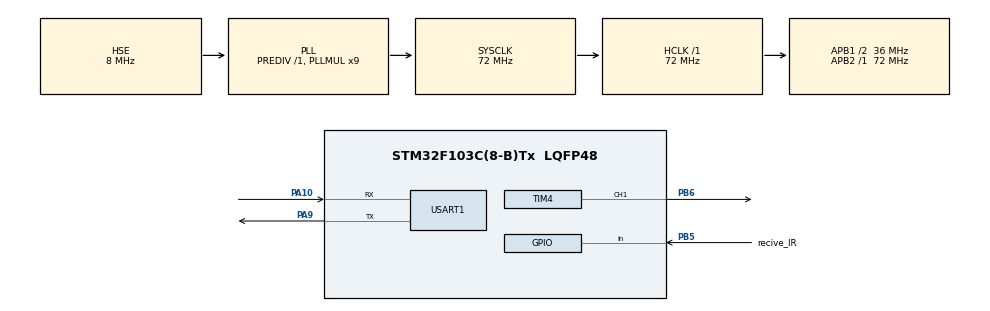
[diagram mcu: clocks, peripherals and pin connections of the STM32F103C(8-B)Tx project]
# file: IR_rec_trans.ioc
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Mcu.Family=STM32F1
Mcu.Name=STM32F103C(8-B)Tx
Mcu.Package=LQFP48
NVIC.PriorityGroup=NVIC_PRIORITYGROUP_4
NVIC.TIM4_IRQn=true\:0\:0\:false\:false\:true\:true\:true
PA10.Mode=Asynchronous
PA10.Signal=USART1_RX
PA13.Mode=Serial_Wire
PA13.Signal=SYS_JTMS-SWDIO
PA14.Mode=Serial_Wire
PA14.Signal=SYS_JTCK-SWCLK
PA9.Mode=Asynchronous
PA9.Signal=USART1_TX
PB5.GPIO_Label=recive_IR
PB5.Signal=GPIO_Input
PB6.Signal=S_TIM4_CH1
PD0-OSC_IN.Mode=HSE-External-Oscillator
PD0-OSC_IN.Signal=RCC_OSC_IN
PD1-OSC_OUT.Mode=HSE-External-Oscillator
PD1-OSC_OUT.Signal=RCC_OSC_OUT
ProjectManager.HeapSize=0x200
ProjectManager.StackSize=0x400
ProjectManager.TargetToolchain=TrueSTUDIO
RCC.AHBFreq_Value=72000000
RCC.APB1CLKDivider=RCC_HCLK_DIV2
RCC.APB1Freq_Value=36000000
RCC.APB1TimFreq_Value=72000000
RCC.APB2Freq_Value=72000000
RCC.APB2TimFreq_Value=72000000
RCC.HCLKFreq_Value=72000000
RCC.PLLMUL=RCC_PLL_MUL9
RCC.PLLSourceVirtual=RCC_PLLSOURCE_HSE
RCC.SYSCLKFreq_VALUE=72000000
RCC.SYSCLKSource=RCC_SYSCLKSOURCE_PLLCLK
RCC.USBFreq_Value=72000000
SH.S_TIM4_CH1.0=TIM4_CH1,PWM Generation1 CH1
TIM4.Channel-PWM\ Generation1\ CH1=TIM_CHANNEL_1
TIM4.OCPolarity_1=TIM_OCPOLARITY_HIGH
TIM4.Period=0
TIM4.Prescaler=0
USART1.VirtualMode=VM_ASYNC
VP_TIM4_VS_ClockSourceINT.Mode=Internal
board=custom

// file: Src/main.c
/* USER CODE BEGIN Header */
/**
  ******************************************************************************
  * @file           : main.c
  * @brief          : Main program body
  ******************************************************************************
  * @attention
  *
  * <h2><center>&copy; Copyright (c) 2019 STMicroelectronics.
  * All rights reserved.</center></h2>
  *
  * This software component is licensed by ST under BSD 3-Clause license,
  * the "License"; You may not use this file except in compliance with the
  * License. You may obtain a copy of the License at:
  *                        opensource.org/licenses/BSD-3-Clause
  *
  ******************************************************************************
  */
/* USER CODE END Header */

#include "main.h"

/* USER CODE BEGIN Includes */
#include "string.h"
#include "IRremote.h"
/* USER CODE END Includes */

TIM_HandleTypeDef htim4;

UART_HandleTypeDef huart1;

void SystemClock_Config(void);
static void MX_GPIO_Init(void);
static void MX_USART1_UART_Init(void);
static void MX_TIM4_Init(void);

int main(void)
{

  /* MCU Configuration--------------------------------------------------------*/

  /* Reset of all peripherals, Initializes the Flash interface and the Systick. */
  HAL_Init();

  /* Configure the system clock */
  SystemClock_Config();

  /* Initialize all configured peripherals */
  MX_GPIO_Init();
  MX_USART1_UART_Init();
  MX_TIM4_Init();
  /* USER CODE BEGIN 2 */

  char trans_str[96] = {0,};
  snprintf(trans_str, 64, "IR-rec-trans https://istarik.ru/blog/stm32/125.html\n");
  HAL_UART_Transmit(&huart1, (uint8_t*)trans_str, strlen(trans_str), 100);

  my_enableIRIn(); // инициализация

  /* USER CODE END 2 */

  /* Infinite loop */
  /* USER CODE BEGIN WHILE */

  static char *decode_str[] = {"UNUSED", "UNKNOWN", "RC5", "RC6", "NEC", "SONY", "PANASONIC", "JVC", "SAMSUNG", "WHYNTER", "AIWA_RC_T501", "LG", "SANYO", "MITSUBISHI", "DISH", "SHARP", "DENON", "PRONTO"};

  while (1)
  {
	////////////////////////////////////////// приём-декодирование ///////////////////////////////////////////////////
	if(my_decode(&results))
	{
		////////// вывод декодированых данных ///////////////
		snprintf(trans_str, 96, "Cod: %p | Type: %s | Bits: %d\n", (void*)results.value, decode_str[results.decode_type + 1], results.bits);
		HAL_UART_Transmit(&huart1, (uint8_t*)trans_str, strlen(trans_str), 100);

		////////// вывод данных в "сыром" виде ///////////////
		/*snprintf(trans_str, 96, "Raw: %d\n", results.rawlen);
		HAL_UART_Transmit(&huart1, (uint8_t*)trans_str, strlen(trans_str), 100);

		for(int i = 1; i < results.rawlen; i++)
		{
			if(i & 1)
			{
				snprintf(trans_str, 96, "%d", results.rawbuf[i] * USECPERTICK);
				HAL_UART_Transmit(&huart1, (uint8_t*)trans_str, strlen(trans_str), 100);
			}
			else
			{
				HAL_UART_Transmit(&huart1, (uint8_t*)"-", 1, 100);
				snprintf(trans_str, 96, "%lu", (uint32_t)results.rawbuf[i] * USECPERTICK);
				HAL_UART_Transmit(&huart1, (uint8_t*)trans_str, strlen(trans_str), 100);
			}

			HAL_UART_Transmit(&huart1, (uint8_t*)" ", 1, 100);
		}

		HAL_UART_Transmit(&huart1, (uint8_t*)"\r\n-----------------\r\n", strlen("\r\n-----------------\r\n"), 100);*/
		////////// конец вывода данных в "сыром" виде ///////////////

		HAL_Delay(300); // небольшая пауза (типа от "дребезга"), а то будет ловить следующий сигнал
		my_resume(); // рестарт приёма (нужно обязательно)
	}

	////////////////////////////////////////// отправка декодированного сигнала ///////////////////////////////////////////////////
	// Cod: 0x707048b7 | Type: SAMSUNG | Bits: 32
	/*uint32_t cod_but = 0;
	cod_but = 0x707048b7; // код кнопки полученый при декодировании

	sendSAMSUNG(cod_but, 32); // протокол полученый при декодировании, код кнопки и длина пакета в битах (Cod: 0x707048b7 | Type: SAMSUNG | Bits: 32)
	my_enableIRIn(); // переинициализирование приёма (нужна обязательно)
	HAL_Delay(2000);*/

	/////////////////////////////////// отправка НЕ декодированного сигнала, в сыром виде /////////////////////////////////////////
	// Cod: 0xa32ab931 | Type: UNKNOWN | Bits: 32
	// Raw: 24
	// 1300 -400 1300 -400 450 -1200 1300 -400 1300 -400 450 -1200 500 -1200 450 -1250 450 -1200 500 -1200 450 -1250 1300

	/*uint8_t khz = 38; // частоту указать экспериментальным путём, основные используемые от 36 до 40 кГц
	unsigned int raw_signal[] = {1300, 400, 1300, 400, 450, 1200, 1300, 400, 1300, 400, 450, 1200, 500, 1200, 450, 1250, 450, 1200, 500, 1200, 450, 1250, 1300};

	sendRaw(raw_signal, sizeof(raw_signal) / sizeof(raw_signal[0]), khz);
	my_enableIRIn(); // переинициализирование приёма (нужна обязательно)
	HAL_Delay(2000);*/

    /* USER CODE END WHILE */

  }
}

void SystemClock_Config(void)
{
  RCC_OscInitTypeDef RCC_OscInitStruct = {0};
  RCC_ClkInitTypeDef RCC_ClkInitStruct = {0};

  /** Initializes the CPU, AHB and APB busses clocks
  */
  RCC_OscInitStruct.OscillatorType = RCC_OSCILLATORTYPE_HSE;
  RCC_OscInitStruct.HSEState = RCC_HSE_ON;
  RCC_OscInitStruct.HSEPredivValue = RCC_HSE_PREDIV_DIV1;
  RCC_OscInitStruct.HSIState = RCC_HSI_ON;
  RCC_OscInitStruct.PLL.PLLState = RCC_PLL_ON;
  RCC_OscInitStruct.PLL.PLLSource = RCC_PLLSOURCE_HSE;
  RCC_OscInitStruct.PLL.PLLMUL = RCC_PLL_MUL9;
  if (HAL_RCC_OscConfig(&RCC_OscInitStruct) != HAL_OK)
  {
    Error_Handler();
  }
  /** Initializes the CPU, AHB and APB busses clocks
  */
  RCC_ClkInitStruct.ClockType = RCC_CLOCKTYPE_HCLK|RCC_CLOCKTYPE_SYSCLK
                              |RCC_CLOCKTYPE_PCLK1|RCC_CLOCKTYPE_PCLK2;
  RCC_ClkInitStruct.SYSCLKSource = RCC_SYSCLKSOURCE_PLLCLK;
  RCC_ClkInitStruct.AHBCLKDivider = RCC_SYSCLK_DIV1;
  RCC_ClkInitStruct.APB1CLKDivider = RCC_HCLK_DIV2;
  RCC_ClkInitStruct.APB2CLKDivider = RCC_HCLK_DIV1;

  if (HAL_RCC_ClockConfig(&RCC_ClkInitStruct, FLASH_LATENCY_2) != HAL_OK)
  {
    Error_Handler();
  }
}

static void MX_TIM4_Init(void)
{

  TIM_ClockConfigTypeDef sClockSourceConfig = {0};
  TIM_MasterConfigTypeDef sMasterConfig = {0};
  TIM_OC_InitTypeDef sConfigOC = {0};

  htim4.Instance = TIM4;
  htim4.Init.Prescaler = 0;
  htim4.Init.CounterMode = TIM_COUNTERMODE_UP;
  htim4.Init.Period = 0;
  htim4.Init.ClockDivision = TIM_CLOCKDIVISION_DIV1;
  htim4.Init.AutoReloadPreload = TIM_AUTORELOAD_PRELOAD_DISABLE;
  if (HAL_TIM_Base_Init(&htim4) != HAL_OK)
  {
    Error_Handler();
  }
  sClockSourceConfig.ClockSource = TIM_CLOCKSOURCE_INTERNAL;
  if (HAL_TIM_ConfigClockSource(&htim4, &sClockSourceConfig) != HAL_OK)
  {
    Error_Handler();
  }
  if (HAL_TIM_PWM_Init(&htim4) != HAL_OK)
  {
    Error_Handler();
  }
  sMasterConfig.MasterOutputTrigger = TIM_TRGO_RESET;
  sMasterConfig.MasterSlaveMode = TIM_MASTERSLAVEMODE_DISABLE;
  if (HAL_TIMEx_MasterConfigSynchronization(&htim4, &sMasterConfig) != HAL_OK)
  {
    Error_Handler();
  }
  sConfigOC.OCMode = TIM_OCMODE_PWM1;
  sConfigOC.Pulse = 0;
  sConfigOC.OCPolarity = TIM_OCPOLARITY_HIGH;
  sConfigOC.OCFastMode = TIM_OCFAST_DISABLE;
  if (HAL_TIM_PWM_ConfigChannel(&htim4, &sConfigOC, TIM_CHANNEL_1) != HAL_OK)
  {
    Error_Handler();
  }
  HAL_TIM_MspPostInit(&htim4);

}

static void MX_USART1_UART_Init(void)
{

  huart1.Instance = USART1;
  huart1.Init.BaudRate = 115200;
  huart1.Init.WordLength = UART_WORDLENGTH_8B;
  huart1.Init.StopBits = UART_STOPBITS_1;
  huart1.Init.Parity = UART_PARITY_NONE;
  huart1.Init.Mode = UART_MODE_TX_RX;
  huart1.Init.HwFlowCtl = UART_HWCONTROL_NONE;
  huart1.Init.OverSampling = UART_OVERSAMPLING_16;
  if (HAL_UART_Init(&huart1) != HAL_OK)
  {
    Error_Handler();
  }

}

static void MX_GPIO_Init(void)
{
  GPIO_InitTypeDef GPIO_InitStruct = {0};

  /* GPIO Ports Clock Enable */
  __HAL_RCC_GPIOD_CLK_ENABLE();
  __HAL_RCC_GPIOA_CLK_ENABLE();
  __HAL_RCC_GPIOB_CLK_ENABLE();

  /*Configure GPIO pin : recive_IR_Pin */
  GPIO_InitStruct.Pin = recive_IR_Pin;
  GPIO_InitStruct.Mode = GPIO_MODE_INPUT;
  GPIO_InitStruct.Pull = GPIO_NOPULL;
  HAL_GPIO_Init(recive_IR_GPIO_Port, &GPIO_InitStruct);

}

void Error_Handler(void)
{
}

/************************ (C) COPYRIGHT STMicroelectronics *****END OF FILE****/
